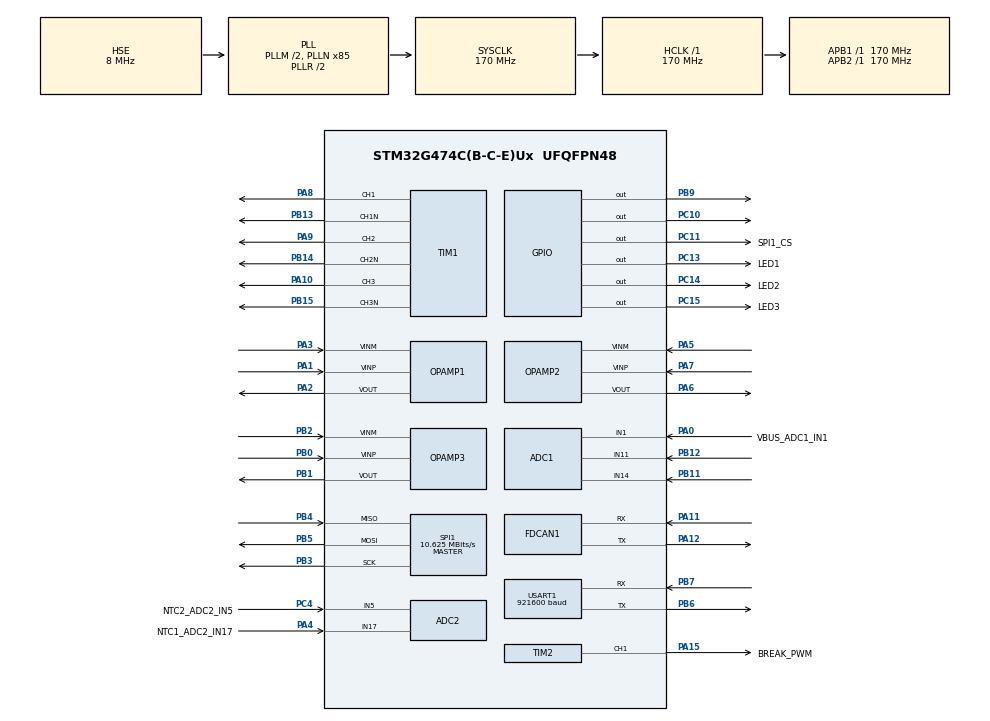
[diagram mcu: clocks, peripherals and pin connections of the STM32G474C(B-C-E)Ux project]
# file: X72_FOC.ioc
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ADC1.Channel-3\#ChannelRegularConversion=ADC_CHANNEL_1
ADC1.Channel-4\#ChannelRegularConversion=ADC_CHANNEL_TEMPSENSOR_ADC1
ADC1.Channel-5\#ChannelRegularConversion=ADC_CHANNEL_14
ADC1.Channel-6\#ChannelRegularConversion=ADC_CHANNEL_11
ADC1.ContinuousConvMode=ENABLE
ADC1.DMAContinuousRequests=ENABLE
ADC1.EnableInjectedConversion=ENABLE
ADC1.EnableRegularConversion=ENABLE
ADC1.ExternalTrigInjecConv=ADC_EXTERNALTRIGINJEC_T1_TRGO
ADC1.ExternalTrigInjecConvEdge=ADC_EXTERNALTRIGINJECCONV_EDGE_RISING
ADC1.InjNumberOfConversion=1
ADC1.InjectedChannel-1\#ChannelInjectedConversion=ADC_CHANNEL_3
ADC1.InjectedOffsetNumber-1\#ChannelInjectedConversion=ADC_OFFSET_NONE
ADC1.InjectedRank-1\#ChannelInjectedConversion=1
ADC1.InjectedSamplingTime-1\#ChannelInjectedConversion=ADC_SAMPLETIME_2CYCLES_5
ADC1.NbrOfConversion=4
ADC1.NbrOfConversionFlag=1
ADC1.OffsetNumber-3\#ChannelRegularConversion=ADC_OFFSET_NONE
ADC1.OffsetNumber-4\#ChannelRegularConversion=ADC_OFFSET_NONE
ADC1.OffsetNumber-5\#ChannelRegularConversion=ADC_OFFSET_NONE
ADC1.OffsetNumber-6\#ChannelRegularConversion=ADC_OFFSET_NONE
ADC1.Rank-3\#ChannelRegularConversion=1
ADC1.Rank-4\#ChannelRegularConversion=2
ADC1.Rank-5\#ChannelRegularConversion=3
ADC1.Rank-6\#ChannelRegularConversion=4
ADC1.SamplingTime-3\#ChannelRegularConversion=ADC_SAMPLETIME_24CYCLES_5
ADC1.SamplingTime-4\#ChannelRegularConversion=ADC_SAMPLETIME_24CYCLES_5
ADC1.SamplingTime-5\#ChannelRegularConversion=ADC_SAMPLETIME_2CYCLES_5
ADC1.SamplingTime-6\#ChannelRegularConversion=ADC_SAMPLETIME_2CYCLES_5
ADC1.master=1
ADC2.Channel-2\#ChannelRegularConversion=ADC_CHANNEL_17
ADC2.Channel-3\#ChannelRegularConversion=ADC_CHANNEL_5
ADC2.ContinuousConvMode=ENABLE
ADC2.DMAContinuousRequests=ENABLE
ADC2.EnableInjectedConversion=ENABLE
ADC2.EnableRegularConversion=ENABLE
ADC2.ExternalTrigInjecConv=ADC_EXTERNALTRIGINJEC_T1_TRGO
ADC2.InjNumberOfConversion=1
ADC2.InjectedChannel-1\#ChannelInjectedConversion=ADC_CHANNEL_3
ADC2.InjectedOffsetNumber-1\#ChannelInjectedConversion=ADC_OFFSET_NONE
ADC2.InjectedRank-1\#ChannelInjectedConversion=1
ADC2.InjectedSamplingTime-1\#ChannelInjectedConversion=ADC_SAMPLETIME_2CYCLES_5
ADC2.NbrOfConversion=2
ADC2.NbrOfConversionFlag=1
ADC2.OffsetNumber-2\#ChannelRegularConversion=ADC_OFFSET_NONE
ADC2.OffsetNumber-3\#ChannelRegularConversion=ADC_OFFSET_NONE
ADC2.Rank-2\#ChannelRegularConversion=1
ADC2.Rank-3\#ChannelRegularConversion=2
ADC2.SamplingTime-2\#ChannelRegularConversion=ADC_SAMPLETIME_24CYCLES_5
ADC2.SamplingTime-3\#ChannelRegularConversion=ADC_SAMPLETIME_24CYCLES_5
ADC3.Channel-4\#ChannelRegularConversion=ADC_CHANNEL_VREFINT
ADC3.DMAContinuousRequests=ENABLE
ADC3.EnableInjectedConversion=ENABLE
ADC3.EnableRegularConversion=ENABLE
ADC3.ExternalTrigInjecConv=ADC_EXTERNALTRIGINJEC_T1_TRGO
ADC3.InjNumberOfConversion=1
ADC3.InjectedChannel-3\#ChannelInjectedConversion=ADC_CHANNEL_1
ADC3.InjectedOffsetNumber-3\#ChannelInjectedConversion=ADC_OFFSET_NONE
ADC3.InjectedRank-3\#ChannelInjectedConversion=1
ADC3.InjectedSamplingTime-3\#ChannelInjectedConversion=ADC_SAMPLETIME_2CYCLES_5
ADC3.NbrOfConversionFlag=1
ADC3.OffsetNumber-4\#ChannelRegularConversion=ADC_OFFSET_NONE
ADC3.Rank-4\#ChannelRegularConversion=1
ADC3.SamplingTime-4\#ChannelRegularConversion=ADC_SAMPLETIME_2CYCLES_5
ADC3.master=1
Dma.ADC1.2.Direction=DMA_PERIPH_TO_MEMORY
Dma.ADC1.2.EventEnable=DISABLE
Dma.ADC1.2.Instance=DMA1_Channel3
Dma.ADC1.2.MemDataAlignment=DMA_MDATAALIGN_HALFWORD
Dma.ADC1.2.MemInc=DMA_MINC_ENABLE
Dma.ADC1.2.Mode=DMA_CIRCULAR
Dma.ADC1.2.PeriphDataAlignment=DMA_PDATAALIGN_HALFWORD
Dma.ADC1.2.PeriphInc=DMA_PINC_DISABLE
Dma.ADC1.2.Polarity=HAL_DMAMUX_REQ_GEN_RISING
Dma.ADC1.2.Priority=DMA_PRIORITY_MEDIUM
Dma.ADC1.2.RequestNumber=1
Dma.ADC1.2.SignalID=NONE
Dma.ADC1.2.SyncEnable=DISABLE
Dma.ADC1.2.SyncPolarity=HAL_DMAMUX_SYNC_NO_EVENT
Dma.ADC1.2.SyncRequestNumber=1
Dma.ADC1.2.SyncSignalID=NONE
Dma.ADC2.3.Direction=DMA_PERIPH_TO_MEMORY
Dma.ADC2.3.EventEnable=DISABLE
Dma.ADC2.3.Instance=DMA1_Channel4
Dma.ADC2.3.MemDataAlignment=DMA_MDATAALIGN_HALFWORD
Dma.ADC2.3.MemInc=DMA_MINC_ENABLE
Dma.ADC2.3.Mode=DMA_CIRCULAR
Dma.ADC2.3.PeriphDataAlignment=DMA_PDATAALIGN_HALFWORD
Dma.ADC2.3.PeriphInc=DMA_PINC_DISABLE
Dma.ADC2.3.Polarity=HAL_DMAMUX_REQ_GEN_RISING
Dma.ADC2.3.Priority=DMA_PRIORITY_MEDIUM
Dma.ADC2.3.RequestNumber=1
Dma.ADC2.3.SignalID=NONE
Dma.ADC2.3.SyncEnable=DISABLE
Dma.ADC2.3.SyncPolarity=HAL_DMAMUX_SYNC_NO_EVENT
Dma.ADC2.3.SyncRequestNumber=1
Dma.ADC2.3.SyncSignalID=NONE
Dma.ADC3.6.Direction=DMA_PERIPH_TO_MEMORY
Dma.ADC3.6.EventEnable=DISABLE
Dma.ADC3.6.Instance=DMA1_Channel7
Dma.ADC3.6.MemDataAlignment=DMA_MDATAALIGN_HALFWORD
Dma.ADC3.6.MemInc=DMA_MINC_ENABLE
Dma.ADC3.6.Mode=DMA_CIRCULAR
Dma.ADC3.6.PeriphDataAlignment=DMA_PDATAALIGN_HALFWORD
Dma.ADC3.6.PeriphInc=DMA_PINC_DISABLE
Dma.ADC3.6.Polarity=HAL_DMAMUX_REQ_GEN_RISING
Dma.ADC3.6.Priority=DMA_PRIORITY_MEDIUM
Dma.ADC3.6.RequestNumber=1
Dma.ADC3.6.SignalID=NONE
Dma.ADC3.6.SyncEnable=DISABLE
Dma.ADC3.6.SyncPolarity=HAL_DMAMUX_SYNC_NO_EVENT
Dma.ADC3.6.SyncRequestNumber=1
Dma.ADC3.6.SyncSignalID=NONE
Dma.Request0=SPI1_TX
Dma.Request1=SPI1_RX
Dma.Request2=ADC1
Dma.Request3=ADC2
Dma.Request4=USART1_RX
Dma.Request5=USART1_TX
Dma.Request6=ADC3
Dma.SPI1_RX.1.Direction=DMA_PERIPH_TO_MEMORY
Dma.SPI1_RX.1.EventEnable=DISABLE
Dma.SPI1_RX.1.Instance=DMA1_Channel2
Dma.SPI1_RX.1.MemDataAlignment=DMA_MDATAALIGN_BYTE
Dma.SPI1_RX.1.MemInc=DMA_MINC_ENABLE
Dma.SPI1_RX.1.Mode=DMA_NORMAL
Dma.SPI1_RX.1.PeriphDataAlignment=DMA_PDATAALIGN_BYTE
Dma.SPI1_RX.1.PeriphInc=DMA_PINC_DISABLE
Dma.SPI1_RX.1.Polarity=HAL_DMAMUX_REQ_GEN_RISING
Dma.SPI1_RX.1.Priority=DMA_PRIORITY_HIGH
Dma.SPI1_RX.1.RequestNumber=1
Dma.SPI1_RX.1.SignalID=NONE
Dma.SPI1_RX.1.SyncEnable=DISABLE
Dma.SPI1_RX.1.SyncPolarity=HAL_DMAMUX_SYNC_NO_EVENT
Dma.SPI1_RX.1.SyncRequestNumber=1
Dma.SPI1_RX.1.SyncSignalID=NONE
Dma.SPI1_TX.0.Direction=DMA_MEMORY_TO_PERIPH
Dma.SPI1_TX.0.EventEnable=DISABLE
Dma.SPI1_TX.0.Instance=DMA1_Channel1
Dma.SPI1_TX.0.MemDataAlignment=DMA_MDATAALIGN_BYTE
Dma.SPI1_TX.0.MemInc=DMA_MINC_ENABLE
Dma.SPI1_TX.0.Mode=DMA_NORMAL
Dma.SPI1_TX.0.PeriphDataAlignment=DMA_PDATAALIGN_BYTE
Dma.SPI1_TX.0.PeriphInc=DMA_PINC_DISABLE
Dma.SPI1_TX.0.Polarity=HAL_DMAMUX_REQ_GEN_RISING
Dma.SPI1_TX.0.Priority=DMA_PRIORITY_HIGH
Dma.SPI1_TX.0.RequestNumber=1
Dma.SPI1_TX.0.SignalID=NONE
Dma.SPI1_TX.0.SyncEnable=DISABLE
Dma.SPI1_TX.0.SyncPolarity=HAL_DMAMUX_SYNC_NO_EVENT
Dma.SPI1_TX.0.SyncRequestNumber=1
Dma.SPI1_TX.0.SyncSignalID=NONE
Dma.USART1_RX.4.Direction=DMA_PERIPH_TO_MEMORY
Dma.USART1_RX.4.EventEnable=DISABLE
Dma.USART1_RX.4.Instance=DMA1_Channel5
Dma.USART1_RX.4.MemDataAlignment=DMA_MDATAALIGN_BYTE
Dma.USART1_RX.4.MemInc=DMA_MINC_ENABLE
Dma.USART1_RX.4.Mode=DMA_NORMAL
Dma.USART1_RX.4.PeriphDataAlignment=DMA_PDATAALIGN_BYTE
Dma.USART1_RX.4.PeriphInc=DMA_PINC_DISABLE
Dma.USART1_RX.4.Polarity=HAL_DMAMUX_REQ_GEN_RISING
Dma.USART1_RX.4.Priority=DMA_PRIORITY_LOW
Dma.USART1_RX.4.RequestNumber=1
Dma.USART1_RX.4.SignalID=NONE
Dma.USART1_RX.4.SyncEnable=DISABLE
Dma.USART1_RX.4.SyncPolarity=HAL_DMAMUX_SYNC_NO_EVENT
Dma.USART1_RX.4.SyncRequestNumber=1
Dma.USART1_RX.4.SyncSignalID=NONE
Dma.USART1_TX.5.Direction=DMA_MEMORY_TO_PERIPH
Dma.USART1_TX.5.EventEnable=DISABLE
Dma.USART1_TX.5.Instance=DMA1_Channel6
Dma.USART1_TX.5.MemDataAlignment=DMA_MDATAALIGN_BYTE
Dma.USART1_TX.5.MemInc=DMA_MINC_ENABLE
Dma.USART1_TX.5.Mode=DMA_NORMAL
Dma.USART1_TX.5.PeriphDataAlignment=DMA_PDATAALIGN_BYTE
Dma.USART1_TX.5.PeriphInc=DMA_PINC_DISABLE
Dma.USART1_TX.5.Polarity=HAL_DMAMUX_REQ_GEN_RISING
Dma.USART1_TX.5.Priority=DMA_PRIORITY_LOW
Dma.USART1_TX.5.RequestNumber=1
Dma.USART1_TX.5.SignalID=NONE
Dma.USART1_TX.5.SyncEnable=DISABLE
Dma.USART1_TX.5.SyncPolarity=HAL_DMAMUX_SYNC_NO_EVENT
Dma.USART1_TX.5.SyncRequestNumber=1
Dma.USART1_TX.5.SyncSignalID=NONE
FDCAN1.CalculateBaudRateNominal=1000000
FDCAN1.CalculateTimeBitNominal=1000
FDCAN1.CalculateTimeQuantumNominal=100.0
FDCAN1.DataPrescaler=17
FDCAN1.DataTimeSeg1=7
FDCAN1.DataTimeSeg2=2
FDCAN1.ExtFiltersNbr=5
FDCAN1.FrameFormat=FDCAN_FRAME_FD_NO_BRS
FDCAN1.NominalPrescaler=17
FDCAN1.NominalTimeSeg1=7
FDCAN1.NominalTimeSeg2=2
FDCAN1.StdFiltersNbr=5
Mcu.Family=STM32G4
Mcu.Name=STM32G474C(B-C-E)Ux
Mcu.Package=UFQFPN48
Mcu.UserConstants=TIM_1_8_PERIOD_CLOCKS,4250;TIM_1_8_PWM_HZ,20000;TIM_1_8_PWM_DT,0.000050;TIM_1_8_DEADTIME_CLOCKS,80;Init_PWM,TIM_1_8_PERIOD_CLOCKS/2;TIM_1_8_CLOCK_HZ,170000000;PWM_ADC_INJECT_TIME,TIM_1_8_PERIOD_CLOCKS-1
NVIC.ADC1_2_IRQn=true\:0\:0\:false\:false\:true\:true\:true\:true
NVIC.DMA1_Channel1_IRQn=true\:1\:0\:true\:false\:true\:true\:true\:true
NVIC.DMA1_Channel2_IRQn=true\:1\:0\:true\:false\:true\:true\:true\:true
NVIC.DMA1_Channel5_IRQn=true\:7\:0\:true\:false\:true\:true\:true\:true
NVIC.DMA1_Channel6_IRQn=true\:7\:0\:true\:false\:true\:true\:true\:true
NVIC.FDCAN1_IT0_IRQn=true\:5\:0\:true\:false\:true\:true\:true\:true
NVIC.FDCAN1_IT1_IRQn=true\:5\:0\:true\:false\:true\:true\:true\:true
NVIC.PriorityGroup=NVIC_PRIORITYGROUP_4
NVIC.SPI1_IRQn=true\:1\:0\:true\:false\:true\:true\:true\:true
NVIC.TIM1_UP_TIM16_IRQn=true\:5\:0\:true\:false\:true\:true\:true\:true
NVIC.TIM5_IRQn=true\:9\:0\:true\:false\:false\:true\:true\:true
NVIC.TIM6_DAC_IRQn=true\:4\:0\:true\:false\:true\:true\:true\:true
NVIC.USART1_IRQn=true\:8\:0\:true\:false\:false\:true\:true\:true
OPAMP1.PowerMode=OPAMP_POWERMODE_HIGHSPEED
OPAMP2.PowerMode=OPAMP_POWERMODE_HIGHSPEED
OPAMP3.PowerMode=OPAMP_POWERMODE_HIGHSPEED
PA0.GPIO_Label=VBUS_ADC1_IN1
PA0.Mode=IN1-Single-Ended
PA0.Signal=ADC1_IN1
PA1.Mode=Standalone
PA1.Signal=OPAMP1_VINP
PA10.Signal=S_TIM1_CH3
PA11.GPIO_Speed=GPIO_SPEED_FREQ_HIGH
PA11.Mode=FDCAN_Activate
PA11.Signal=FDCAN1_RX
PA12.GPIO_Speed=GPIO_SPEED_FREQ_HIGH
PA12.Mode=FDCAN_Activate
PA12.Signal=FDCAN1_TX
PA15.GPIO_Label=BREAK_PWM
PA15.Signal=S_TIM2_CH1
PA2.Signal=SharedAnalog_PA2
PA3.Mode=Standalone
PA3.Signal=OPAMP1_VINM
PA4.GPIO_Label=NTC1_ADC2_IN17
PA4.Mode=IN17-Single-Ended
PA4.Signal=ADC2_IN17
PA5.Mode=Standalone
PA5.Signal=OPAMP2_VINM
PA6.Signal=SharedAnalog_PA6
PA7.Mode=Standalone
PA7.Signal=OPAMP2_VINP
PA8.Signal=S_TIM1_CH1
PA9.Signal=S_TIM1_CH2
PB0.Mode=Standalone
PB0.Signal=OPAMP3_VINP
PB1.Signal=SharedAnalog_PB1
PB11.Mode=IN14-Single-Ended
PB11.Signal=ADC1_IN14
PB12.Mode=IN11-Single-Ended
PB12.Signal=ADC1_IN11
PB13.Mode=PWM Generation1 CH1 CH1N
PB13.Signal=TIM1_CH1N
PB14.Mode=PWM Generation2 CH2 CH2N
PB14.Signal=TIM1_CH2N
PB15.Mode=PWM Generation3 CH3 CH3N
PB15.Signal=TIM1_CH3N
PB2.Mode=Standalone
PB2.Signal=OPAMP3_VINM
PB3.GPIO_PuPd=GPIO_PULLUP
PB3.GPIO_Speed=GPIO_SPEED_FREQ_VERY_HIGH
PB3.Mode=Full_Duplex_Master
PB3.Signal=SPI1_SCK
PB4.GPIO_PuPd=GPIO_PULLUP
PB4.GPIO_Speed=GPIO_SPEED_FREQ_VERY_HIGH
PB4.Mode=Full_Duplex_Master
PB4.Signal=SPI1_MISO
PB5.GPIO_Speed=GPIO_SPEED_FREQ_VERY_HIGH
PB5.Mode=Full_Duplex_Master
PB5.Signal=SPI1_MOSI
PB6.Mode=Asynchronous
PB6.Signal=USART1_TX
PB7.Mode=Asynchronous
PB7.Signal=USART1_RX
PB9.GPIO_PuPd=GPIO_PULLDOWN
PB9.Signal=GPIO_Output
PC10.Signal=GPIO_Output
PC11.GPIO_Label=SPI1_CS
PC11.Signal=GPIO_Output
PC13.GPIO_Label=LED1
PC13.PinState=GPIO_PIN_SET
PC13.Signal=GPIO_Output
PC14-OSC32_IN.GPIO_Label=LED2
PC14-OSC32_IN.PinState=GPIO_PIN_SET
PC14-OSC32_IN.Signal=GPIO_Output
PC15-OSC32_OUT.GPIO_Label=LED3
PC15-OSC32_OUT.PinState=GPIO_PIN_SET
PC15-OSC32_OUT.Signal=GPIO_Output
PC4.GPIO_Label=NTC2_ADC2_IN5
PC4.Mode=IN5-Single-Ended
PC4.Signal=ADC2_IN5
PF0-OSC_IN.Mode=HSE-External-Oscillator
PF0-OSC_IN.Signal=RCC_OSC_IN
PF1-OSC_OUT.Mode=HSE-External-Oscillator
PF1-OSC_OUT.Signal=RCC_OSC_OUT
ProjectManager.HeapSize=0x800
ProjectManager.StackSize=0x800
ProjectManager.TargetToolchain=MDK-ARM V5.32
RCC.ADC12Freq_Value=170000000
RCC.ADC345Freq_Value=170000000
RCC.AHBFreq_Value=170000000
RCC.APB1Freq_Value=170000000
RCC.APB1TimFreq_Value=170000000
RCC.APB2Freq_Value=170000000
RCC.APB2TimFreq_Value=170000000
RCC.CortexFreq_Value=170000000
RCC.EXTERNAL_CLOCK_VALUE=12288000
RCC.HCLKFreq_Value=170000000
RCC.HSE_VALUE=8000000
RCC.HSI48_VALUE=48000000
RCC.HSI_VALUE=16000000
RCC.LSE_VALUE=32768
RCC.PLLM=RCC_PLLM_DIV2
RCC.PLLN=85
RCC.PLLSourceVirtual=RCC_PLLSOURCE_HSE
RCC.PREFETCH_ENABLE=1
RCC.SYSCLKFreq_VALUE=170000000
RCC.SYSCLKSource=RCC_SYSCLKSOURCE_PLLCLK
RCC.USBFreq_Value=170000000
RCC.VCOOutputFreq_Value=340000000
SH.S_TIM1_CH1.0=TIM1_CH1,PWM Generation1 CH1 CH1N
SH.S_TIM1_CH2.0=TIM1_CH2,PWM Generation2 CH2 CH2N
SH.S_TIM1_CH3.0=TIM1_CH3,PWM Generation3 CH3 CH3N
SH.S_TIM2_CH1.0=TIM2_CH1,PWM Generation1 CH1
SH.SharedAnalog_PA2.0=OPAMP1_VOUT,Standalone
SH.SharedAnalog_PA2.1=ADC1_IN3,IN3-Single-Ended
SH.SharedAnalog_PA6.0=OPAMP2_VOUT,Standalone
SH.SharedAnalog_PA6.1=ADC2_IN3,IN3-Single-Ended
SH.SharedAnalog_PB1.0=OPAMP3_VOUT,Standalone
SH.SharedAnalog_PB1.1=ADC3_IN1,IN1-Single-Ended
SPI1.BaudRatePrescaler=SPI_BAUDRATEPRESCALER_16
SPI1.CLKPhase=SPI_PHASE_2EDGE
SPI1.CLKPolarity=SPI_POLARITY_HIGH
SPI1.CalculateBaudRate=10.625 MBits/s
SPI1.DataSize=SPI_DATASIZE_8BIT
SPI1.Direction=SPI_DIRECTION_2LINES
SPI1.Mode=SPI_MODE_MASTER
SPI1.VirtualType=VM_MASTER
TIM1.Channel-PWM\ Generation1\ CH1\ CH1N=TIM_CHANNEL_1
TIM1.Channel-PWM\ Generation2\ CH2\ CH2N=TIM_CHANNEL_2
TIM1.Channel-PWM\ Generation3\ CH3\ CH3N=TIM_CHANNEL_3
TIM1.Channel-PWM\ Generation4\ No\ Output=TIM_CHANNEL_4
TIM1.CounterMode=TIM_COUNTERMODE_CENTERALIGNED1
TIM1.DeadTime=50
TIM1.OCMode_PWM-PWM\ Generation1\ CH1\ CH1N=TIM_OCMODE_PWM2
TIM1.OCMode_PWM-PWM\ Generation2\ CH2\ CH2N=TIM_OCMODE_PWM2
TIM1.OCMode_PWM-PWM\ Generation3\ CH3\ CH3N=TIM_OCMODE_PWM2
TIM1.OCMode_PWM-PWM\ Generation4\ No\ Output=TIM_OCMODE_PWM2
TIM1.OCNPolarity_1=TIM_OCNPOLARITY_HIGH
TIM1.OCPolarity_1=TIM_OCPOLARITY_HIGH
TIM1.OffStateIDLEMode=TIM_OSSI_ENABLE
TIM1.OffStateRunMode=TIM_OSSR_ENABLE
TIM1.PeriodNoDither=TIM_1_8_PERIOD_CLOCKS
TIM1.PulseNoDither_1=Init_PWM
TIM1.PulseNoDither_2=Init_PWM
TIM1.PulseNoDither_3=Init_PWM
TIM1.PulseNoDither_4=1
TIM1.TIM_MasterOutputTrigger=TIM_TRGO_OC4REF
TIM1.TIM_MasterSlaveMode=TIM_MASTERSLAVEMODE_ENABLE
TIM16.PeriodNoDither=1000-1
TIM16.Prescaler=170-1
TIM2.Channel-PWM\ Generation1\ CH1=TIM_CHANNEL_1
TIM2.PeriodNoDither=8500-1
TIM5.PeriodNoDither=34000-1
TIM5.Prescaler=0
TIM6.PeriodNoDither=1000-1
TIM6.Prescaler=170-1
USART1.BaudRate=921600
USART1.VirtualMode-Asynchronous=VM_ASYNC
VP_ADC1_TempSens_Input.Mode=IN-TempSens
VP_ADC1_Vref_Input.Mode=IN-Vrefint
VP_ADC3_Vref_Input.Mode=IN-Vrefint
VP_SYS_VS_DBSignals.Mode=DisableDeadBatterySignals
VP_TIM16_VS_ClockSourceINT.Mode=Enable_Timer
VP_TIM1_VS_no_output4.Mode=PWM Generation4 No Output
VP_TIM5_VS_ClockSourceINT.Mode=Internal
VP_TIM6_VS_ClockSourceINT.Mode=Enable_Timer
board=custom

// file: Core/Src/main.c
/* USER CODE BEGIN Header */
/**
  ******************************************************************************
  * @file           : main.c
  * @brief          : Main program body
  ******************************************************************************
  * @attention
  *
  * Copyright (c) 2026 STMicroelectronics.
  * All rights reserved.
  *
  * This software is licensed under terms that can be found in the LICENSE file
  * in the root directory of this software component.
  * If no LICENSE file comes with this software, it is provided AS-IS.
  *
  ******************************************************************************
  */
/* USER CODE END Header */
#include "main.h"
#include "adc.h"
#include "dma.h"
#include "fdcan.h"
#include "opamp.h"
#include "spi.h"
#include "tim.h"
#include "usart.h"
#include "gpio.h"

/* USER CODE BEGIN Includes */
#include "bsp_servo.h"
#include "servo_cmd.h"
#include "can_proto.h"
#include "mavlink_host.h"
/* USER CODE END Includes */

void SystemClock_Config(void);

/* USER CODE BEGIN 0 */

/* 构建身份提示（2026-11-22）：改 bsp_servo.h 的 PROD_BUILD 切换。
 * 放 USER CODE 区，CubeMX 重新生成不会丢。
 * 注意：armclang 把 #warning 和 #pragma message 都算作警告，
 * 所以两种构建都会显示 "1 Warning(s)"、UV4 退出码为 1。
 * 脚本判成败请 grep "0 Error(s)"，不要看 $?。 */
/* 只在生产构建告警：需要提醒的恰恰是"以为在开发构建、其实测试支架没了"
 * 这个方向；开发构建保持 0 警告，不打扰日常。 */
#if (PROD_BUILD != 0)
#warning "PROD_BUILD=1 (production): CAN test harness + ident fault-injection DISABLED"
#endif

/* USER CODE END 0 */

int main(void)
{

  /* MCU Configuration--------------------------------------------------------*/

  /* Reset of all peripherals, Initializes the Flash interface and the Systick. */
  HAL_Init();

  /* Configure the system clock */
  SystemClock_Config();

  /* Initialize all configured peripherals */
  MX_GPIO_Init();
  MX_DMA_Init();
  MX_ADC1_Init();
  MX_ADC2_Init();
  MX_FDCAN1_Init();
  MX_OPAMP1_Init();
  MX_OPAMP2_Init();
  MX_OPAMP3_Init();
  MX_SPI1_Init();
  MX_TIM1_Init();
  MX_ADC3_Init();
  MX_TIM2_Init();
  MX_USART1_UART_Init();
  MX_TIM6_Init();
  MX_TIM16_Init();
  MX_TIM5_Init();
  /* USER CODE BEGIN 2 */
  Servo_Init();
  /* CAN FD 正常模式启动：MX_FDCAN1_Init 只做了外设初始化（READY），
   * 这里配全局过滤器并 Start（1 Mbit/s 标称 / 5 Mbit/s 数据、BRS 开）。
   * 失败不阻塞启动 —— CAN 只影响通信，不影响 FOC。 */
  CanProto_Init();
  /* 看门狗放在**所有初始化之后**启动：Servo_Init 里有 Flash 参数恢复与
   * 编码器首帧，耗时不确定，先让它们跑完再上狗，避免启动阶段被复位。
   * 超时 250 ms；喂狗在主循环，不在 1 ms 中断里 —— 见 bsp_servo.c 的说明。 */
  BspServo_WdgInit();
  /* USER CODE END 2 */

  /* Infinite loop */
  while (1)
  {

    /* USER CODE BEGIN 3 */
    /*
     * 命令解析与回显都放主循环（最低优先级）：
     * 20 kHz 控制环在中断里、100 Hz 遥测在 TIM6 里，这里只做"非阻塞尝试发送"，
     * 绝不进中断上下文抢串口。
     */
    ServoCmd_Poll();
    /* MAVLink 操作指令分发（2026-11-18）：帧已在 RXNE 字节流里由 ServoCmd_Poll
     * 收好，这里做 decode→门卫→set→回读→应答。非阻塞，UART 忙则下拍重试。 */
    MavHost_Task();
    /* 喂狗必须在主循环：1 ms 定时器中断还在跑而主循环卡死，正是 2026-11-17
     * 那次 "! 命令把主循环钉死、遥测照发但命令全无响应" 的故障形态。
     * 若在中断里喂，这种情况永远不会被复位。 */
    BspServo_WdgKick();
  }
  /* USER CODE END 3 */
}

void SystemClock_Config(void)
{
  RCC_OscInitTypeDef RCC_OscInitStruct = {0};
  RCC_ClkInitTypeDef RCC_ClkInitStruct = {0};

  /** Configure the main internal regulator output voltage
  */
  HAL_PWREx_ControlVoltageScaling(PWR_REGULATOR_VOLTAGE_SCALE1_BOOST);

  /** Initializes the RCC Oscillators according to the specified parameters
  * in the RCC_OscInitTypeDef structure.
  */
  RCC_OscInitStruct.OscillatorType = RCC_OSCILLATORTYPE_HSE;
  RCC_OscInitStruct.HSEState = RCC_HSE_ON;
  RCC_OscInitStruct.PLL.PLLState = RCC_PLL_ON;
  RCC_OscInitStruct.PLL.PLLSource = RCC_PLLSOURCE_HSE;
  RCC_OscInitStruct.PLL.PLLM = RCC_PLLM_DIV2;
  RCC_OscInitStruct.PLL.PLLN = 85;
  RCC_OscInitStruct.PLL.PLLP = RCC_PLLP_DIV2;
  RCC_OscInitStruct.PLL.PLLQ = RCC_PLLQ_DIV2;
  RCC_OscInitStruct.PLL.PLLR = RCC_PLLR_DIV2;
  if (HAL_RCC_OscConfig(&RCC_OscInitStruct) != HAL_OK)
  {
    Error_Handler();
  }

  /** Initializes the CPU, AHB and APB buses clocks
  */
  RCC_ClkInitStruct.ClockType = RCC_CLOCKTYPE_HCLK|RCC_CLOCKTYPE_SYSCLK
                              |RCC_CLOCKTYPE_PCLK1|RCC_CLOCKTYPE_PCLK2;
  RCC_ClkInitStruct.SYSCLKSource = RCC_SYSCLKSOURCE_PLLCLK;
  RCC_ClkInitStruct.AHBCLKDivider = RCC_SYSCLK_DIV1;
  RCC_ClkInitStruct.APB1CLKDivider = RCC_HCLK_DIV1;
  RCC_ClkInitStruct.APB2CLKDivider = RCC_HCLK_DIV1;

  if (HAL_RCC_ClockConfig(&RCC_ClkInitStruct, FLASH_LATENCY_4) != HAL_OK)
  {
    Error_Handler();
  }
}

void Error_Handler(void)
{
  __disable_irq();
  while (1)
  {
  }
}
